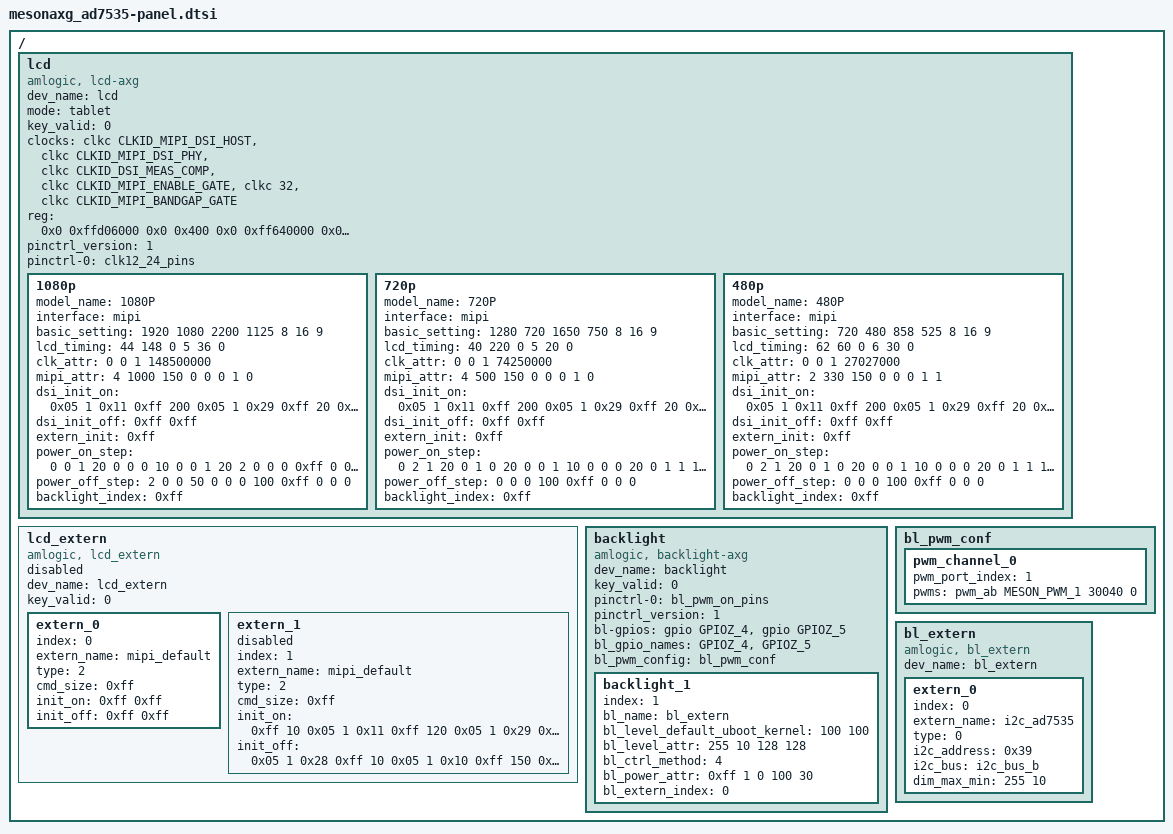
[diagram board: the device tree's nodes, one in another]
/*
 * Copyright (c) 2018-2019, Sonos, Inc.
 *
 * SPDX-License-Identifier:     GPL-2.0
 */

/ {
	lcd{
		compatible = "amlogic, lcd-axg";
		dev_name = "lcd";
		mode = "tablet";
		status = "okay";
		key_valid = <0>;
		/*  FIXME optimo - a113 cleanup
		clocks = <&clkc CLKID_MIPI_DSI_HOST
			&clkc CLKID_MIPI_DSI_PHY
			&clkc CLKID_DSI_MEAS_COMP
			&clkc CLKID_MIPI_ENABLE_GATE
			&clkc CLKID_GPIO_CLK12_GATE
			&clkc CLKID_MIPI_BANDGAP_GATE>;
		*/
		clocks = <&clkc CLKID_MIPI_DSI_HOST
			&clkc CLKID_MIPI_DSI_PHY
			&clkc CLKID_DSI_MEAS_COMP
			&clkc CLKID_MIPI_ENABLE_GATE
			&clkc 32
			&clkc CLKID_MIPI_BANDGAP_GATE>;
		clock-names = "dsi_host_gate",
			"dsi_phy_gate",
			"dsi_meas",
			"mipi_enable_gate",
			"clk12_enable_gate",
			"mipi_bandgap_gate";
		reg = <0x0 0xffd06000 0x0 0x400
			   0x0 0xff640000 0x0 0x100>;
		pinctrl_version = <1>; /* for uboot */
		pinctrl-names =  "clk12";
		pinctrl-0 = <&clk12_24_pins>;

		/* power type:
		 *    (0=cpu_gpio, 1=pmu_gpio, 2=signal,3=extern, 0xff=ending)
		 * power index:
		 *    (point gpios_index, or extern_index,0xff=invalid)
		 * power value:(0=output low, 1=output high, 2=input)
		 * power delay:(unit in ms)
		 */

		//this is the timing setting for ad7535
		1080p{
			model_name = "1080P";
				/*interface(ttl,lvds,mipi)*/
			interface = "mipi";
			basic_setting = <1920 1080 /*h_active, v_active*/
				2200 1125 /*h_period, v_period*/
				8 /*lcd_bits*/
				16 9>; /*screen_widht, screen_height*/
			lcd_timing = <44 148 0 /*hs_width,hs_bp,hs_pol*/
				5 36 0>; /*vs_width,vs_bp,vs_pol*/
			clk_attr = <0 /*fr_adj_type(0=clock,1=htotal,2=vtotal)*/
				0 /*clk_ss_level*/
				1 /*clk_auto_generate*/
				148500000>; /*pixel_clk(unit in Hz)*/
			/*
			 * !!IMPORTANT!!
			 * The mipi_attr lane_num setting below MUST match the
			 * switch statement in adv7533_mode_set() otherwise
			 * nothing will work!
			 */
			mipi_attr = <4 /*lane_num*/
				1000 /*bit_rate_max(MHz)*/
				150 /*factor(*100, default 0 for auto)*/
				0 /*operation_mode_init(0=video, 1=command)*/
				0 /*operation_mode_display(0=video, 1=command)*/
				0 /*
				   *video_mode_type
				   *(0=sync_pulse,1=sync_event,2=burst)
				   */
				1 /*clk_always_hs(0=disable,1=enable)*/
				0>; /*phy_switch(0=auto,1=standard,2=slow)*/
				/* dsi_init: data_type, num, data... */
			dsi_init_on =  <0x05 1 0x11
                                       0xff 200     /*delay(ms)*/
                                       0x05 1 0x29
                                       0xff 20     /*delay(ms)*/
                                       0xff 0xff>; /*ending*/
			dsi_init_off = <0xff 0xff>; /*ending*/
				/* extern_init: 0xff for invalid */
			extern_init = <0xff>;
				/* power step: type,index,value,delay(ms) */
			power_on_step = <0 0 1 20
					0 0 0 10
					0 0 1 20
					2 0 0 0
					0xff 0 0 0>;
			power_off_step = <2 0 0 50
					0 0 0 100
					0xff 0 0 0>;
			backlight_index = <0xff>; //don't use backlight_1 any more,use ADV7533 as DRM connector, initialed by drm/bridge/adv7511_drv.c
		};
		720p{
			model_name = "720P";
				/*interface(ttl,lvds,mipi)*/
			interface = "mipi";
			basic_setting = <1280 720 /*h_active, v_active*/
				1650 750 /*h_period, v_period*/
				8 /*lcd_bits*/
				16 9>; /*screen_widht, screen_height*/
			lcd_timing = <40 220 0 /*hs_width,hs_bp,hs_pol*/
				5 20 0>; /*vs_width,vs_bp,vs_pol*/
			clk_attr = <0 /*fr_adj_type(0=clock,1=htotal,2=vtotal)*/
				0 /*clk_ss_level*/
				1 /*clk_auto_generate*/
				74250000>; /*pixel_clk(unit in Hz)*/
			/*
			 * !!IMPORTANT!!
			 * The mipi_attr lane_num setting below MUST match the
			 * switch statement in adv7533_mode_set() otherwise
			 * nothing will work!
			 */
			mipi_attr = <4 /*lane_num*/
				500 /*bit_rate_max(MHz)*/
				150 /*factor(*100, default 0 for auto)*/
				0 /*operation_mode_init(0=video, 1=command)*/
				0 /*operation_mode_display(0=video, 1=command)*/
				0 /*
				   *video_mode_type
				   *(0=sync_pulse,1=sync_event,2=burst)
				   */
				1 /*clk_always_hs(0=disable,1=enable)*/
				0>; /*phy_switch(0=auto,1=standard,2=slow)*/
				/* dsi_init: data_type, num, data... */
			dsi_init_on =  <0x05 1 0x11
                                       0xff 200     /*delay(ms)*/
                                       0x05 1 0x29
                                       0xff 20     /*delay(ms)*/
                                       0xff 0xff>; /*ending*/
			dsi_init_off = <0xff 0xff>; /*ending*/
				/* extern_init: 0xff for invalid */
			extern_init = <0xff>;
				/* power step: type,index,value,delay(ms) */
			power_on_step = <0 2 1 20
					0 1 0 20
					0 0 1 10
					0 0 0 20
					0 1 1 100
					3 0 0 10
					2 0 0 10
					0xff 0 0 0>;
			power_off_step = <0 0 0 100
					0xff 0 0 0>;
			backlight_index = <0xff>; //don't use backlight_1 any more,use ADV7533 as DRM connector, initialed by drm/bridge/adv7511_drv.c
		};
		480p{	/* 720x480 */
			model_name = "480P";
				/*interface(ttl,lvds,mipi)*/
			interface = "mipi";
			basic_setting = <720 480 /*h_active, v_active*/
				858 525 /*h_period, v_period*/
				8 /*lcd_bits*/
				16 9>; /*screen_widht, screen_height*/
			lcd_timing = <62 60 0 /*hs_width,hs_bp,hs_pol*/
				6 30 0>; /*vs_width,vs_bp,vs_pol*/
			clk_attr = <0 /*fr_adj_type(0=clock,1=htotal,2=vtotal)*/
				0 /*clk_ss_level*/
				1 /*clk_auto_generate*/
				27027000>; /*pixel_clk(unit in Hz)*/
			/*
			 * !!IMPORTANT!!
			 * The mipi_attr lane_num setting below MUST match the
			 * switch statement in adv7533_mode_set() otherwise
			 * nothing will work!
			 */
			mipi_attr = <2 /*lane_num*/
				330 /*bit_rate_max(MHz)*/
				150 /*factor(*100, default 0 for auto)*/
				0 /*operation_mode_init(0=video, 1=command)*/
				0 /*operation_mode_display(0=video, 1=command)*/
				0 /*
				   *video_mode_type
				   *(0=sync_pulse,1=sync_event,2=burst)
				   */
				1 /*clk_always_hs(0=disable,1=enable)*/
				1>; /*phy_switch(0=auto,1=standard,2=slow)*/
				/* dsi_init: data_type, num, data... */
			dsi_init_on =  <0x05 1 0x11
                                       0xff 200     /*delay(ms)*/
                                       0x05 1 0x29
                                       0xff 20     /*delay(ms)*/
                                       0xff 0xff>; /*ending*/
			dsi_init_off = <0xff 0xff>; /*ending*/
				/* extern_init: 0xff for invalid */
			extern_init = <0xff>;
				/* power step: type,index,value,delay(ms) */
			power_on_step = <0 2 1 20
					0 1 0 20
					0 0 1 10
					0 0 0 20
					0 1 1 100
					3 0 0 10
					2 0 0 10
					0xff 0 0 0>;
			power_off_step = <0 0 0 100
					0xff 0 0 0>;
			backlight_index = <0xff>; //don't use backlight_1 any more,use ADV7533 as DRM connector, initialed by drm/bridge/adv7511_drv.c
		};
	};

	// this is used to initial panel by mipi cmd
	lcd_extern{
		compatible = "amlogic, lcd_extern";
		dev_name = "lcd_extern";
		status = "disabled";//not used on sonos platform
		key_valid = <0>;
		//pinctrl-name ="extern_pins";
		//pinctrl-0 ="&clk12_24_pins";

		extern_0{
			index = <0>;
			extern_name = "mipi_default";/*default*/
			status = "okay";
			type = <2>; /* 0=i2c, 1=spi, 2=mipi */
			cmd_size = <0xff>;
			init_on = <
				0xff 0xff>; /*ending*/
			init_off = <
				0xff 0xff>; /*ending*/
		};

		extern_1{
			index = <1>;
			extern_name = "mipi_default";/*TV070WSM*/
			status = "disable";
			type = <2>; /* 0=i2c, 1=spi, 2=mipi */
			cmd_size = <0xff>;
			init_on = <
				0xff 10
				0x05 1 0x11
				0xff 120  /* delay 120ms */
				0x05 1 0x29
				0xff 130   /* delay 130ms */
				0xFF 0xFF>; /*ending*/
			init_off = <
				0x05 1 0x28 /* display off */
				0xff 10     /* delay 10ms */
				0x05 1 0x10 /* sleep in */
				0xff 150      /* delay 150ms */
				0xff 0xff>; /*ending*/
		};

	};

	backlight{
		compatible = "amlogic, backlight-axg";
		dev_name = "backlight";
		status = "okay"; //not used on sonos platform
		key_valid = <0>;
		pinctrl-names = "pwm_on";
		pinctrl-0 = <&bl_pwm_on_pins>;
		pinctrl_version = <1>; /* for uboot */

		/* pwm port: PWM_A, PWM_B, PWM_C, PWM_D, PWM_VS*/
		/* power index:(point gpios_index, 0xff=invalid)
		 * power value:(0=output low, 1=output high, 2=input)
		 * power delay:(unit in ms)
		 */
		bl-gpios = <&gpio GPIOZ_4 GPIO_ACTIVE_HIGH
			&gpio GPIOZ_5 GPIO_ACTIVE_HIGH>;
		bl_gpio_names = "GPIOZ_4","GPIOZ_5";
		bl_pwm_config = <&bl_pwm_conf>;

		backlight_1{
			index = <1>;
			bl_name = "bl_extern";
			bl_level_default_uboot_kernel = <100 100>;
			bl_level_attr = <255 10 /*max, min*/
				128 128>; /*mid, mid_mapping*/
			bl_ctrl_method = <4>; /*1=pwm, 2=pwm_combo, 4=extern*/
			/* no need power control */
			bl_power_attr = <0xff  //en_gpio_index
				1 0 // on_value, off_value
				100 30>; // on_delay(ms), off_delay(ms)
			bl_extern_index = <0>; //this is the index value of bl_extern/extern_0
		};
	};

	bl_pwm_conf:bl_pwm_conf{
		pwm_channel_0 {
			pwm_port_index = <1>;
			pwms = <&pwm_ab MESON_PWM_1 30040 0>;
		};
	};

	//this is backlight controll, i2c can be used here.
	// So , I think we can use this to init AD7535 by i2c
	bl_extern{
		compatible = "amlogic, bl_extern";
		dev_name = "bl_extern";
		status = "okay";

		extern_0{
			index = <0>;
			// this extern_name is related with
			// drivers/amlogic/media/vout/backlight/bl_extern/i2c_lp8556.c
			extern_name = "i2c_ad7535";

			type = <0>; /*0=i2c, 1=spi, 2=mipi*/
			i2c_address = <0x39>; /*7bit i2c address*/
			i2c_bus = "i2c_bus_b";
			dim_max_min = <255 10>;
		};
	};


};/* end of panel */

